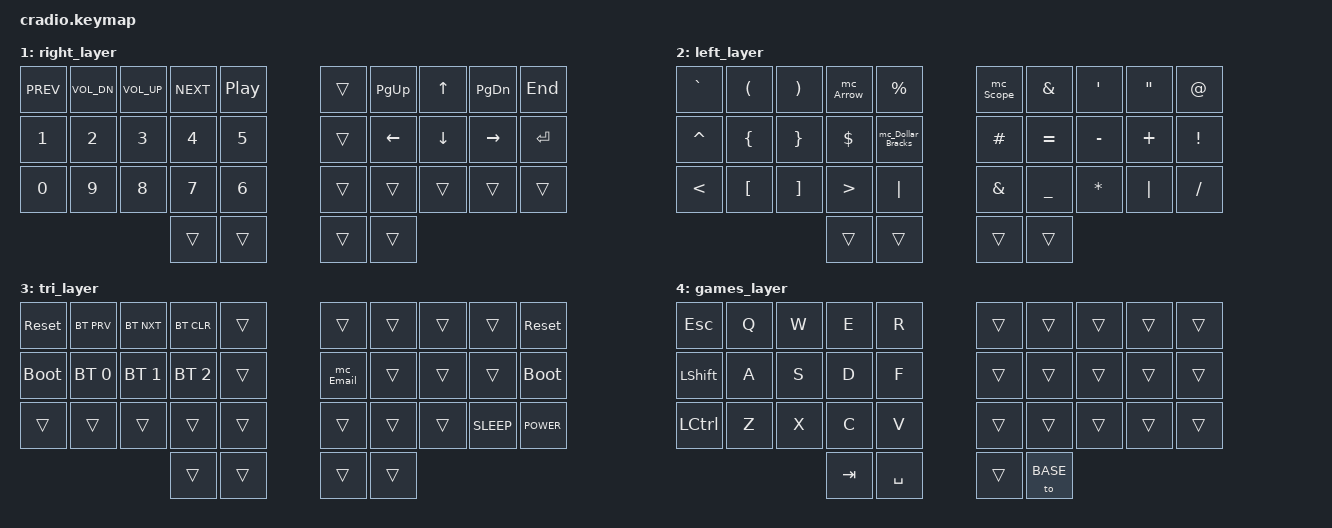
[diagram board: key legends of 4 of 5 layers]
// Copyright (c) 2022 The ZMK Contributors
// SPDX-License-Identifier: MIT

#include <behaviors.dtsi>
#include <dt-bindings/zmk/keys.h>
#include <dt-bindings/zmk/bt.h>
#include <dt-bindings/zmk/mouse.h>
#include "34keys.h"

/ {
    behaviors {
        #include "behaviors.dtsi"
    };

    conditional_layers {
        compatible = "zmk,conditional-layers";
        tri_layer {
            if-layers = <1 2>;
            then-layer = <3>;
        };
    };

    combos {
        #include "combos.dtsi"
    };

    macros {
        #include "macros.dtsi"
    };


    keymap {
        compatible = "zmk,keymap";
 
        default_layer {
            bindings = <
        //╭──────────┬──────────┬──────────┬──────────┬──────────╮   ╭──────────┬──────────┬──────────┬──────────┬──────────╮
        //│  B       │  L       │  D       │  C       │  V       │   │  J       │  F       │  O       │  U       │ ' "      │
            &kp B      &kp L      &kp D      &kp C      &kp V         &kp J      &kp F      &kp O      &kp U      &kp SQT
        //├──────────┼──────────┼──────────┼──────────┼───── ────┤   ├──────────┼──────────┼──────────┼──────────┼──────────┤
        //│  N       │  R       │  S       │  T       │  G       │   │  Y       │  H       │  A       │  E       │  I       │
            HRML(N,        R,         T,         S)     &kp G          &kp Y      HRMR(H,        A,         E,        I)
        //├──────────┼──────────┼──────────┼──────────┼────── ───┤   ├──────────┼──────────┼──────────┼──────────┼──────────┤
        //│  X       │  Q       │  M       │  W        │  Z      │   │  K       │  M       │ , <      │ . >      │ / ?      │
            &kp X      &kp Q      &kp M      &kp W      &kp Z          &kp K      &kp P      &kp COMMA  &kp DOT    &kp FSLH
        //╰──────────┴──────────┴─────────┼─────────── ┼─────────┤  ├─────────────────────┼──────────┴──────────┴──────────╯
                                       &nav_lt NAV DEL  &key_repeat    &kp SPACE    &sym_lt SYM BSPC
        //                                ╰────────────┴──────────╯  ╰────────────┴────────────────╯
            >;
        };

   right_layer {
            bindings = <
        //╭────────── ┬─────────  ─┬────────   ─┬──────────┬──────────╮   ╭──────────┬──────────┬──────────┬──────────┬──────────╮
        //│ INSERT    │            │            │          │          │   │ HOME     │ PAGE DN  │ PAGE UP  │ END      │  :       │
           &kp C_PREV  &kp C_VOL_DN &kp C_VOL_UP &kp C_NEXT  &kp C_PP       &trans   &kp PG_UP   &kp UP    &kp PG_DN   &kp END  
        //├────────── ┼───────  ───┼───────   ──┼──────────┼──────────┤   ├──────────┼──────────┼──────────┼──────────┼──────────┤
        //│ 1         │  2         │  3         │  4       │  5       │   │ LEFT     │ DOWN     │ UP       │ RIGHT    │  ENT     │
            &kp N1     &kp N2        &kp N3      &kp N4     &kp N5          &trans    &kp LEFT    &kp DOWN   &kp RIGHT  &kp RET
        //├──────── ──┼── ─── ─────┼────────  ──┼──────────┼──────────┤   ├──────────┼──────────┼──────────┼──────────┼──────────┤
        //│ 0         │  9         │  8         │  7       │  6       │   │          │          │          │          │          │
            &kp N0     &kp N9        &kp N8      &kp N7     &kp N6         &trans     &trans     &trans     &trans     &trans
        //╰────────── ┴─────────  ─┴──────────┼──────────┼──────────┤   ├──────────┼──────────┼──────────┴──────────┴──────────╯
                                               &trans      &trans        &trans     &trans
           //                                 ╰──────────┴──────────╯   ╰──────────┴──────────╯
            >;
        };

    left_layer {
            bindings = <
            &kp GRAVE      &kp LPAR   &kp RPAR &mc_Arrow  &kp PRCNT          &mc_Scope  &kp AMPS  &kp QUOT   &kp DQT   &kp AT
            &kp CARET   &kp LBRC   &kp RBRC   &kp DLLR   &mc_Dollar_Bracks      &kp HASH  &kp EQUAL  &kp MINUS  &kp PLUS   &kp EXCL
            &kp LT      &kp LBKT   &kp RBKT    &kp GT    &kp PIPE         &kp AMPS   &kp UNDER  &kp STAR   &kp PIPE   &kp FSLH
                                              &trans     &trans         &trans     &trans
            >;
        };

    tri_layer {
            bindings = <
        //╭──────────┬──────────┬──────────┬──────────┬──────────╮   ╭──────────┬──────────┬──────────┬──────────┬──────────╮
        //│ RESET    │          │          │          │PROFILE 0 │   │          │          │          │          │  RESET   │
           &sys_reset  &bt BT_PRV  &bt BT_NXT  &bt BT_CLR  &trans     &trans     &trans     &trans     &trans    &sys_reset 
        //├──────────┼──────────┼──────────┼──────────┼──────────┤   ├──────────┼──────────┼──────────┼──────────┼──────────┤
        //│BOOTLOADER│          │          │          │PROFILE 1 │   │          │          │          │          │BOOTLOADER│
          &bootloader  &bt BT_SEL 0 &bt BT_SEL 1 &bt BT_SEL 2  &trans   &mc_Email  &trans  &trans   &trans    &bootloader
        //├──────────┼──────────┼──────────┼──────────┼──────────┤   ├──────────┼──────────┼──────────┼──────────┼──────────┤
        //│          │          │          │ CLEAR BT │PROFILE 2 │   │          │          │          │          │          │
            &trans     &trans     &trans    &trans      &trans          &trans     &trans     &trans    &kp K_SLEEP  &kp K_POWER
        //╰──────────┴──────────┴──────────┼──────────┼──────────┤   ├──────────┼──────────┼──────────┴──────────┴──────────╯
                                             &trans     &trans         &trans     &trans
        //                                 ╰──────────┴──────────╯   ╰──────────┴──────────╯
            >;
        };

    games_layer {
            bindings = <
        //╭──────────┬──────────┬──────────┬──────────┬──────────╮   ╭──────────┬──────────┬──────────┬──────────┬──────────╮
        //│ RESET    │          │          │          │ │   │          │          │          │          │          │
            &kp ESC     &kp Q        &kp W     &kp E     &kp R        &trans      &trans   &trans     &trans       &trans 
        //├──────────┼──────────┼──────────┼──────────┼──────────┤   ├──────────┼──────────┼──────────┼──────────┼──────────┤
        //│          │          │          │          │          │          │          │          │          │  
           &kp LSHFT   &kp A       &kp S        &kp D    &kp F          &trans   &trans     &trans     &trans     &trans    
        //├──────────┼──────────┼──────────┼──────────┼──────────┤   ├──────────┼──────────┼──────────┼──────────┼──────────┤
        //│          │          │          │          │          │   │          │          │          │          │          │
            &kp LCTRL  &kp Z       &kp X       &kp C     &kp V         &trans     &trans     &trans    &trans   &trans
        //╰──────────┴──────────┴──────────┼──────────┼──────────┤   ├──────────┼──────────┼──────────┴──────────┴──────────╯
                                             &kp TAB    &kp SPACE        &trans   &to BASE
        //                                 ╰──────────┴──────────╯   ╰──────────┴──────────╯
            
            >;
        };


    };
};
